# GD32C231 register map
File version: 1.0
CPU: CM23 r0p0, little endian, MPU, FPU, 4 interrupt priority bits
Registers are 32-bit, read-write, reset 0x0 unless marked. A register's access mark holds for its fields unless they carry their own. Offsets are from the block's base; [hi:lo] are bit positions; {n}, {i} and the like mark numbered series.

## FWDGT — free watchdog timer
Base 0x40003000
0x00 CTL wo — Control register
  [15:0] CMD — Key value
0x04 PSC — Prescaler register
  [2:0] PSC — Prescaler divider
0x08 RLD reset 0xFFF — Reload register
  [11:0] RLD — Watchdog counter reload value
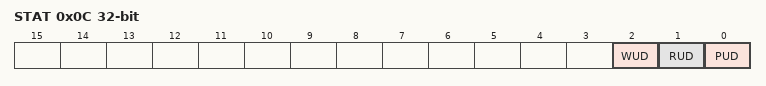
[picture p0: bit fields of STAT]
0x0C STAT ro — Status register
  [2] WUD — Watchdog counter window value update
  [1] RUD — Watchdog counter reload value update
  [0] PUD — Watchdog prescaler value update
0x10 WND reset 0xFFF — Window register
  [11:0] WND — Watchdog counter window value

## GPIOA — General-purpose I/Os
Base 0x48000000
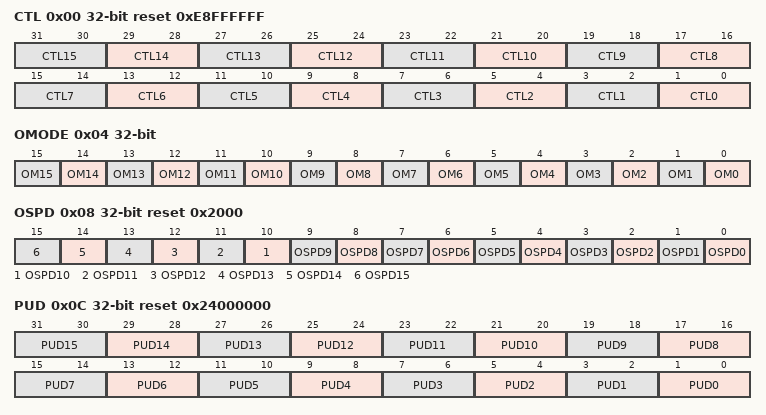
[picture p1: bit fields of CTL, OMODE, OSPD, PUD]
0x00 CTL reset 0xE8FFFFFF — GPIO port control register
  [2n+1:2n] CTL{n} (n=0..15) — Port x configuration bits (y = 0..15)
0x04 OMODE — GPIO port output type register
  [n] OM{n} (n=0..15) — Port x configuration bit {n}
0x08 OSPD reset 0x2000 — GPIO port output speed register
  [n] OSPD{n} (n=0..15) — Port x configuration bits (y = 0..15)
0x0C PUD reset 0x24000000 — GPIO port pull-up/pull-down register
  [2n+1:2n] PUD{n} (n=0..15) — Port x configuration bits (y = 0..15)
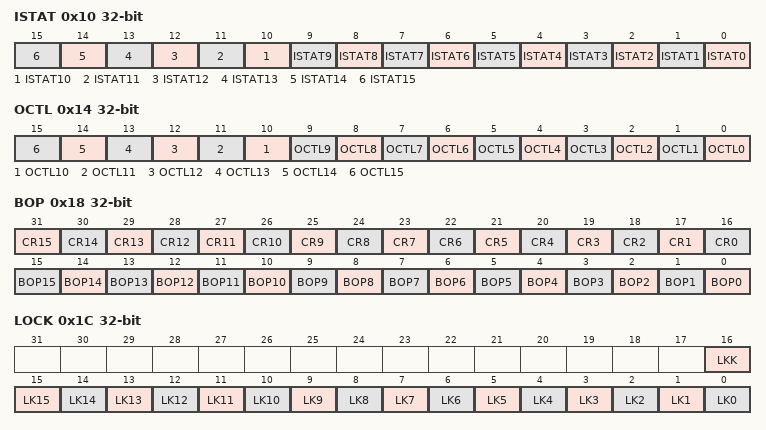
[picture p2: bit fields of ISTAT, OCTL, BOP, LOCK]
0x10 ISTAT ro — GPIO port input data register
  [n] ISTAT{n} (n=0..15) — Port input data (y = 0..15)
0x14 OCTL — GPIO port output data register
  [n] OCTL{n} (n=0..15) — Port output data (y = 0..15)
0x18 BOP wo — GPIO port bit set/reset register
  [n+16] CR{n} (n=1..15) — Port x reset bit y (y = 0..15)
  [16] CR0 — Port x reset bit y (y= 0..15)
  [n] BOP{n} (n=0..15) — Port x set bit y (y= 0..15)
0x1C LOCK — GPIO port configuration lock register
  [16] LKK — Port x lock bit y
  [n] LK{n} (n=0..15) — Port x lock bit y (y= 0..15)
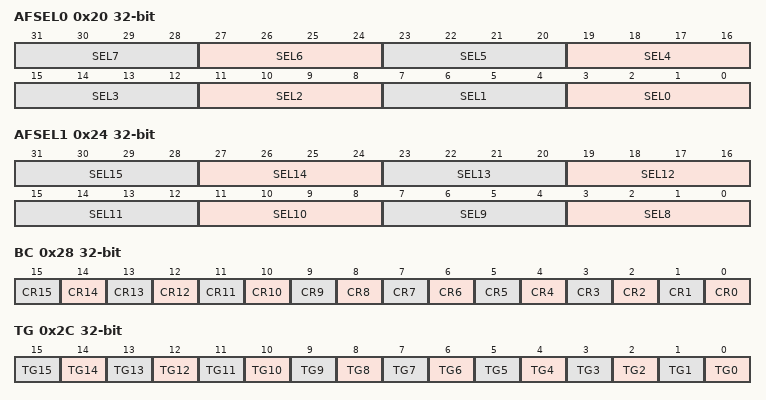
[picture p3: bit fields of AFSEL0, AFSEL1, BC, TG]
0x20 AFSEL0 — GPIO alternate function low register
  [4n+3:4n] SEL{n} (n=0..7) — Alternate function selection for port x bit y (y = 0..7)
0x24 AFSEL1 — GPIO alternate function register 1
  [4n-29:4n-32] SEL{n} (n=8..15) — Alternate function selection for port x bit y (y = 8..15)
0x28 BC wo — Port bit reset register
  [n] CR{n} (n=0..15) — Port cleat bit
0x2C TG wo — Port bit toggle register
  [n] TG{n} (n=0..15) — Port toggle bit

## GPIOB — General-purpose I/Os
Base 0x48000400
Same registers: GPIOC 0x48000800, GPIOD 0x48000C00, GPIOF 0x48001400
Registers as GPIOA; these are added or differ:
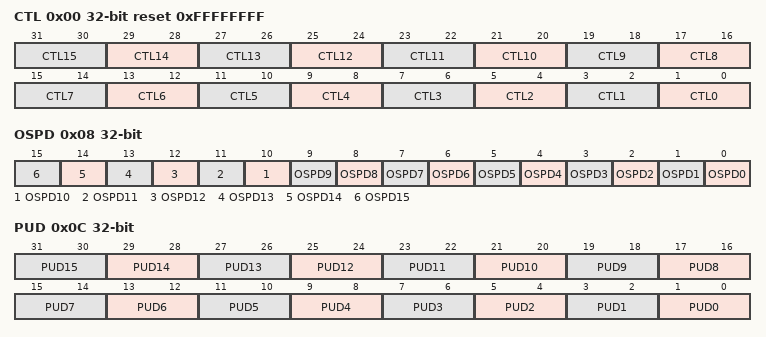
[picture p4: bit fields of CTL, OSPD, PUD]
0x00 CTL reset 0xFFFFFFFF — GPIO port control register
  [2n+1:2n] CTL{n} (n=0..15) — Port x configuration bits (y = 0..15)
0x08 OSPD — GPIO port output speed register
  [n] OSPD{n} (n=0..15) — Port x configuration bits (y = 0..15)
0x0C PUD — GPIO port pull-up/pull-down register
  [2n+1:2n] PUD{n} (n=0..15) — Port x configuration bits (y = 0..15)

## NVIC — Nested Vectored Interrupt Controller
Base 0xE000E100
{0x0+4i} ISER{i} (i=0..15) — Interrupt Set Enable Register
  [31:0] SETENA
0x80 ICER0 — Interrupt Clear Enable register
  [31:0] CLRENA
0x84 ICER1 — Interrupt Clear Enable register
  [31:0] CLRENA
{0x84+4i} ICER{i} (i=2..15) — Interrupt Clear Enable register
  [31:0] CLRENA
{0x100+4i} ISPR{i} (i=0..15) — Interrupt Set-Pending Register
  [31:0] SETPEND
{0x180+4i} ICPR{i} (i=0..15) — Interrupt Clear-Pending register
  [31:0] CLRPEND
{0x200+4i} IABR{i} (i=0..15) — Interrupt Active bit register
  [31:0] IABR
{0x280+4i} ITNS{i} (i=0..15) — Interrupt Active bit register
  [31:0] ITNS
{0x300+i} IPR{i} 8-bit (i=0..31) — Interrupt Priority Register {i}
  [7:0] PRI_{i:02}

## PMU — Power management unit
Base 0x40007000
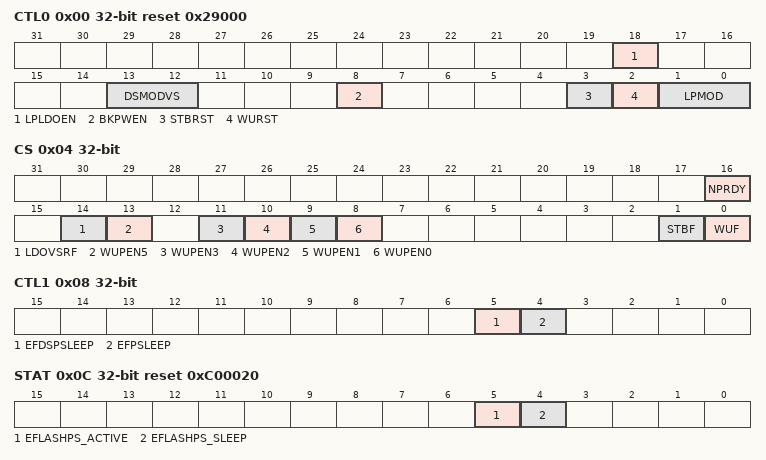
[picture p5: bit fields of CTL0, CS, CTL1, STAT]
0x00 CTL0 reset 0x29000 — Control register 0
  [18] LPLDOEN — Low power LDO enable
  [13:12] DSMODVS — Deep-sleep mode voltage selection.
  [8] BKPWEN — Backup Domain (VCORE_STB) Write Enable
  [3] STBRST — Standby Flag Reset
  [2] WURST — Wakeup Flag Reset
  [1:0] LPMOD — Select the low-power mode to enter when the Cortex-M23 enters SLEEPDEEP mode.
0x04 CS access per field — Control and status register
  [16] NPRDY ro — NPLDO ready flag
  [14] LDOVSRF ro — LDO voltage select ready flag.
  [13] WUPEN5 rw — WKUP Pin5 (PB5) Enable
  [11] WUPEN3 rw — WKUP Pin3 (PA2) enable
  [10] WUPEN2 rw — WKUP Pin2 (PB6) enable
  [9] WUPEN1 rw — WKUP Pin1(PC13 / PA4) enable
  [8] WUPEN0 rw — WKUP Pin0(PA0) enable
  [1] STBF ro — Standby Flag
  [0] WUF ro — Wakeup Flag
0x08 CTL1 — Control register 1
  [5] EFDSPSLEEP — EFLASH power off contrl when MCU enters to Deep-sleep/Deep-sleep1 mode.
  [4] EFPSLEEP — EFLASH power off control when MCU enters to Run/Run1 mode.
0x0C STAT ro reset 0xC00020 — Status register
  [5] EFLASHPS_ACTIVE — EFLASH is in active state.
  [4] EFLASHPS_SLEEP — EFLASH is in sleep state.
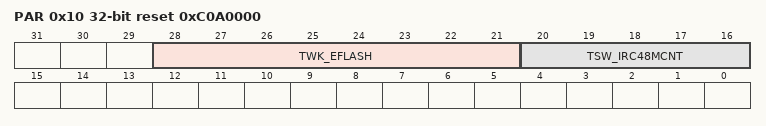
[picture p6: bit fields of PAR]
0x10 PAR reset 0xC0A0000 — Parameter register
  [28:21] TWK_EFLASH — EFLASH wake up from Deep-sleep/Deep-sleep1 mode counter.
  [20:16] TSW_IRC48MCNT — When enter Deep-sleep/Deep-sleep1 mode, switch to IRC48M clock.
